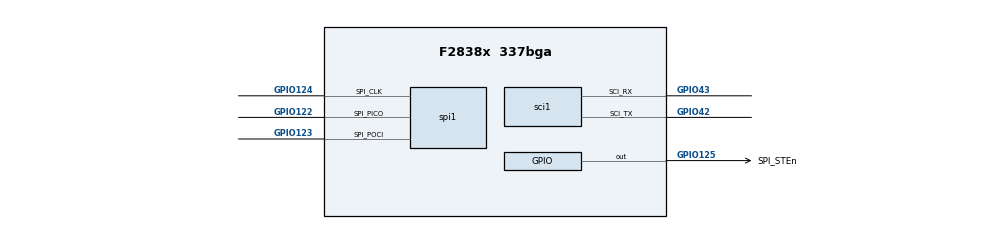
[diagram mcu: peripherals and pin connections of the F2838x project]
/**
 * @cliArgs --device "F2838x" --package "337bga" --part "F2838x_337bga" --context "CPU1" --product "C2000WARE@5.00.00.00"
 * @versions {"tool":"1.17.0+3128"}
 */

/**
 * Import the modules used in this configuration.
 */
const cputimer       = scripting.addModule("/driverlib/cputimer.js", {}, false);
const cputimer1      = cputimer.addInstance();
const device_support = scripting.addModule("/driverlib/device_support.js");
const gpio           = scripting.addModule("/driverlib/gpio.js", {}, false);
const gpio1          = gpio.addInstance();
const sci            = scripting.addModule("/driverlib/sci.js", {}, false);
const sci1           = sci.addInstance();
const spi            = scripting.addModule("/driverlib/spi.js", {}, false);
const spi1           = spi.addInstance();
const sysctl         = scripting.addModule("/driverlib/sysctl.js");

/**
 * Write custom configuration values to the imported modules.
 */
cputimer1.$name          = "BASE_1ms_TIMER";
cputimer1.timerPrescaler = 200;
cputimer1.timerPeriod    = 1000000;

device_support.useStandardCodeStartBranch = false;

gpio1.direction         = "GPIO_DIR_MODE_OUT";
gpio1.writeInitialValue = true;
gpio1.$name             = "SPI_STEn";
gpio1.gpioPin.$assign   = "GPIO125";

sci1.$name                 = "BL_SCI";
sci1.sci.$assign           = "SCIA";
sci1.sci.sci_rxPin.$assign = "GPIO43";
sci1.sci.sci_txPin.$assign = "GPIO42";

spi1.transferProtocol        = "SPI_PROT_POL0PHA1";
spi1.useInterrupts           = false;
spi1.useCase                 = "CUSTOM";
spi1.useInterfacePins        = ["SPI@_CLK","SPI@_SIMO","SPI@_SOMI"];
spi1.bitRate                 = 400000;
spi1.mode                    = "SPI_MODE_CONTROLLER";
spi1.emulationMode           = "SPI_EMULATION_STOP_AFTER_TRANSMIT";
spi1.$name                   = "DISPLAY_SPI";
spi1.spi.$assign             = "SPIC";
spi1.spi.spi_picoPin.$assign = "GPIO122";
spi1.spi.spi_pociPin.$assign = "GPIO123";
spi1.spi.spi_clkPin.$assign  = "GPIO124";

sysctl.enable_SYSCTL_PERIPH_CLK_CLA1      = false;
sysctl.enable_SYSCTL_PERIPH_CLK_DMA       = false;
sysctl.enable_SYSCTL_PERIPH_CLK_TIMER1    = false;
sysctl.enable_SYSCTL_PERIPH_CLK_TIMER2    = false;
sysctl.enable_SYSCTL_PERIPH_CLK_CPUBGCRC  = false;
sysctl.enable_SYSCTL_PERIPH_CLK_CLA1BGCRC = false;
sysctl.enable_SYSCTL_PERIPH_CLK_HRCAL     = false;
sysctl.enable_SYSCTL_PERIPH_CLK_ECAT      = false;
sysctl.enable_SYSCTL_PERIPH_CLK_MPOSTCLK  = false;
sysctl.enable_SYSCTL_PERIPH_CLK_DCC2      = false;
sysctl.enable_SYSCTL_PERIPH_CLK_DCC1      = false;
sysctl.enable_SYSCTL_PERIPH_CLK_DCC0      = false;
sysctl.enable_SYSCTL_PERIPH_CLK_PMBUSA    = false;
sysctl.enable_SYSCTL_PERIPH_CLK_FSIRXH    = false;
sysctl.enable_SYSCTL_PERIPH_CLK_FSIRXG    = false;
sysctl.enable_SYSCTL_PERIPH_CLK_FSIRXF    = false;
sysctl.enable_SYSCTL_PERIPH_CLK_FSIRXE    = false;
sysctl.enable_SYSCTL_PERIPH_CLK_FSIRXD    = false;
sysctl.enable_SYSCTL_PERIPH_CLK_FSIRXC    = false;
sysctl.enable_SYSCTL_PERIPH_CLK_FSIRXB    = false;
sysctl.enable_SYSCTL_PERIPH_CLK_FSITXB    = false;
sysctl.enable_SYSCTL_PERIPH_CLK_FSIRXA    = false;
sysctl.enable_SYSCTL_PERIPH_CLK_FSITXA    = false;
sysctl.enable_SYSCTL_PERIPH_CLK_CLB8      = false;
sysctl.enable_SYSCTL_PERIPH_CLK_CLB7      = false;
sysctl.enable_SYSCTL_PERIPH_CLK_CLB6      = false;
sysctl.enable_SYSCTL_PERIPH_CLK_CLB5      = false;
sysctl.enable_SYSCTL_PERIPH_CLK_CLB4      = false;
sysctl.enable_SYSCTL_PERIPH_CLK_CLB3      = false;
sysctl.enable_SYSCTL_PERIPH_CLK_CLB2      = false;
sysctl.enable_SYSCTL_PERIPH_CLK_CLB1      = false;
sysctl.enable_SYSCTL_PERIPH_CLK_DACC      = false;
sysctl.enable_SYSCTL_PERIPH_CLK_DACB      = false;
sysctl.enable_SYSCTL_PERIPH_CLK_DACA      = false;
sysctl.enable_SYSCTL_PERIPH_CLK_CMPSS8    = false;
sysctl.enable_SYSCTL_PERIPH_CLK_CMPSS7    = false;
sysctl.enable_SYSCTL_PERIPH_CLK_CMPSS6    = false;
sysctl.enable_SYSCTL_PERIPH_CLK_CMPSS5    = false;
sysctl.enable_SYSCTL_PERIPH_CLK_CMPSS4    = false;
sysctl.enable_SYSCTL_PERIPH_CLK_CMPSS3    = false;
sysctl.enable_SYSCTL_PERIPH_CLK_CMPSS2    = false;
sysctl.enable_SYSCTL_PERIPH_CLK_CMPSS1    = false;
sysctl.enable_SYSCTL_PERIPH_CLK_ADCD      = false;
sysctl.enable_SYSCTL_PERIPH_CLK_ADCC      = false;
sysctl.enable_SYSCTL_PERIPH_CLK_ADCB      = false;
sysctl.enable_SYSCTL_PERIPH_CLK_ADCA      = false;
sysctl.enable_SYSCTL_PERIPH_CLK_USBA      = false;
sysctl.enable_SYSCTL_PERIPH_CLK_MCBSPB    = false;
sysctl.enable_SYSCTL_PERIPH_CLK_MCBSPA    = false;
sysctl.enable_SYSCTL_PERIPH_CLK_MCANA     = false;
sysctl.enable_SYSCTL_PERIPH_CLK_CANB      = false;
sysctl.enable_SYSCTL_PERIPH_CLK_CANA      = false;
sysctl.enable_SYSCTL_PERIPH_CLK_I2CB      = false;
sysctl.enable_SYSCTL_PERIPH_CLK_I2CA      = false;
sysctl.enable_SYSCTL_PERIPH_CLK_SPID      = false;
sysctl.enable_SYSCTL_PERIPH_CLK_SPIB      = false;
sysctl.enable_SYSCTL_PERIPH_CLK_SPIA      = false;
sysctl.enable_SYSCTL_PERIPH_CLK_SCID      = false;
sysctl.enable_SYSCTL_PERIPH_CLK_SCIB      = false;
sysctl.enable_SYSCTL_PERIPH_CLK_SD2       = false;
sysctl.enable_SYSCTL_PERIPH_CLK_SD1       = false;
sysctl.enable_SYSCTL_PERIPH_CLK_EQEP3     = false;
sysctl.enable_SYSCTL_PERIPH_CLK_EQEP2     = false;
sysctl.enable_SYSCTL_PERIPH_CLK_EQEP1     = false;
sysctl.enable_SYSCTL_PERIPH_CLK_ECAP7     = false;
sysctl.enable_SYSCTL_PERIPH_CLK_ECAP6     = false;
sysctl.enable_SYSCTL_PERIPH_CLK_ECAP5     = false;
sysctl.enable_SYSCTL_PERIPH_CLK_ECAP4     = false;
sysctl.enable_SYSCTL_PERIPH_CLK_ECAP3     = false;
sysctl.enable_SYSCTL_PERIPH_CLK_ECAP2     = false;
sysctl.enable_SYSCTL_PERIPH_CLK_ECAP1     = false;
sysctl.enable_SYSCTL_PERIPH_CLK_EPWM16    = false;
sysctl.enable_SYSCTL_PERIPH_CLK_EPWM15    = false;
sysctl.enable_SYSCTL_PERIPH_CLK_EPWM14    = false;
sysctl.enable_SYSCTL_PERIPH_CLK_EPWM13    = false;
sysctl.enable_SYSCTL_PERIPH_CLK_EPWM12    = false;
sysctl.enable_SYSCTL_PERIPH_CLK_EPWM11    = false;
sysctl.enable_SYSCTL_PERIPH_CLK_EPWM10    = false;
sysctl.enable_SYSCTL_PERIPH_CLK_EPWM9     = false;
sysctl.enable_SYSCTL_PERIPH_CLK_EPWM8     = false;
sysctl.enable_SYSCTL_PERIPH_CLK_EPWM7     = false;
sysctl.enable_SYSCTL_PERIPH_CLK_EPWM6     = false;
sysctl.enable_SYSCTL_PERIPH_CLK_EPWM5     = false;
sysctl.enable_SYSCTL_PERIPH_CLK_EPWM3     = false;
sysctl.enable_SYSCTL_PERIPH_CLK_EPWM4     = false;
sysctl.enable_SYSCTL_PERIPH_CLK_EPWM2     = false;
sysctl.enable_SYSCTL_PERIPH_CLK_EPWM1     = false;
sysctl.enable_SYSCTL_PERIPH_CLK_EMIF2     = false;
sysctl.enable_SYSCTL_PERIPH_CLK_EMIF1     = false;
sysctl.enable_SYSCTL_PERIPH_CLK_ERAD      = false;
sysctl.enable_SYSCTL_PERIPH_CLK_SCIC      = false;
